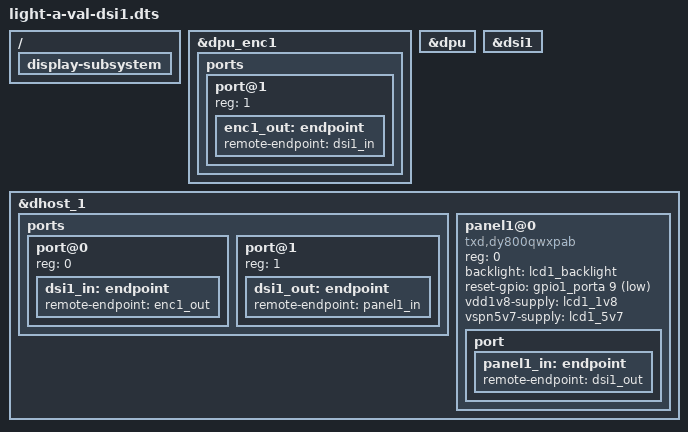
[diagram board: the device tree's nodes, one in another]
/* SPDX-License-Identifier: GPL-2.0 */
/*
 * Copyright (C) 2021 Alibaba Group Holding Limited.
 */

/dts-v1/;

#include "light-a-val.dts"

/ {
	display-subsystem {
		status = "okay";
	};
};

&dpu_enc1 {
	status = "okay";

	ports {
		/* output */
		port@1 {
			reg = <1>;

			enc1_out: endpoint {
				remote-endpoint = <&dsi1_in>;
			};
		};
	};
};

&dpu {
        status = "okay";
};

&dsi1 {
        status = "okay";
};

&dhost_1 {
	ports {
		#address-cells = <1>;
		#size-cells = <0>;

		port@0 {
			reg = <0>;

			dsi1_in: endpoint {
				remote-endpoint = <&enc1_out>;
			};
		};

		port@1 {
			reg = <1>;

			dsi1_out: endpoint {
				remote-endpoint = <&panel1_in>;
			};
		};
	};

	panel1@0 {
		compatible = "txd,dy800qwxpab";
		reg = <0>;
		backlight = <&lcd1_backlight>;
		reset-gpio = <&gpio1_porta 9 1>;		/* active low */
		vdd1v8-supply = <&lcd1_1v8>;
		vspn5v7-supply = <&lcd1_5v7>;

		port {
			panel1_in: endpoint {
				remote-endpoint = <&dsi1_out>;
			};
		};
	};
};
